AUTOSAR XML (schema 4-0-3)
package /AppMode/ApplicationSwComponentTypes
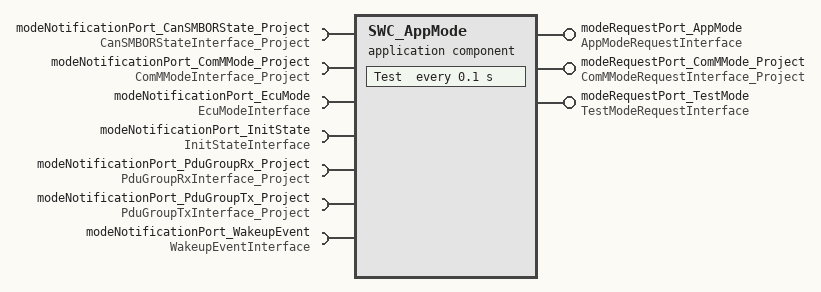
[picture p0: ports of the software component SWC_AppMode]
  application sw component type SWC_AppMode
    7 x require port:
      modeNotificationPort_CanSMBORState_Project: mode-switch-receiver-com-spec{enhanced-mode-api=true, mode-group=CanSMBORState_Project, supports-asynchronous-mode-switch=true}, required-interface=CanSMBORStateInterface_Project
      modeNotificationPort_ComMMode_Project: mode-switch-receiver-com-spec{enhanced-mode-api=true, mode-group=ComMMode_Project, supports-asynchronous-mode-switch=true}, required-interface=ComMModeInterface_Project
      modeNotificationPort_EcuMode: mode-switch-receiver-com-spec{enhanced-mode-api=true, mode-group=EcuMode, supports-asynchronous-mode-switch=true}, required-interface=EcuModeInterface
      modeNotificationPort_InitState: mode-switch-receiver-com-spec{enhanced-mode-api=true, mode-group=InitState, supports-asynchronous-mode-switch=true}, required-interface=InitStateInterface
      modeNotificationPort_PduGroupRx_Project: mode-switch-receiver-com-spec{enhanced-mode-api=true, mode-group=PduGroupRx_Project, supports-asynchronous-mode-switch=true}, required-interface=PduGroupRxInterface_Project
      modeNotificationPort_PduGroupTx_Project: mode-switch-receiver-com-spec{enhanced-mode-api=true, mode-group=PduGroupTx_Project, supports-asynchronous-mode-switch=true}, required-interface=PduGroupTxInterface_Project
      modeNotificationPort_WakeupEvent: mode-switch-receiver-com-spec{enhanced-mode-api=true, mode-group=WakeupEvent, supports-asynchronous-mode-switch=true}, required-interface=WakeupEventInterface
    provide port modeRequestPort_AppMode: nonqueued-sender-com-spec=AppMode, provided-interface=AppModeRequestInterface
    provide port modeRequestPort_ComMMode_Project: nonqueued-sender-com-spec=ComMMode_Project, provided-interface=ComMModeRequestInterface_Project
    provide port modeRequestPort_TestMode: nonqueued-sender-com-spec=TestMode, provided-interface=TestModeRequestInterface
    behavior SwcIB_AppMode: data-type-mapping=[MAP_AppMode, MAP_ComMMode, MAP_PduRouter, MAP_CanSMBORState, MAP_InitState, MAP_CanSMState, MAP_TestModeSR]
      timing event TE_AppMode_Test: start-on-event=Test, period=0.1
        disabled-mode:
          modeNotificationPort_EcuMode.EcuMode.ECUM_STATE_STARTUP_ONE
          modeNotificationPort_EcuMode.EcuMode.ECUM_STATE_STARTUP_THREE
          modeNotificationPort_EcuMode.EcuMode.ECUM_STATE_STARTUP_TWO
      7 x swc mode switch event, all with activation=ON-ENTRY:
        SMSE_Entry_EcuModeSwitched_modeNotificationPort_EcuMode_EcuMode_ECUM_STATE_PREP_SHUTDOWN: start-on-event=EcuModeSwitched, mode=modeNotificationPort_EcuMode.EcuMode.ECUM_STATE_PREP_SHUTDOWN
        SMSE_Entry_EcuModeSwitched_modeNotificationPort_EcuMode_EcuMode_ECUM_STATE_RUN: start-on-event=EcuModeSwitched, mode=modeNotificationPort_EcuMode.EcuMode.ECUM_STATE_RUN
        SMSE_Entry_EcuModeSwitched_modeNotificationPort_EcuMode_EcuMode_ECUM_STATE_SHUTDOWN: start-on-event=EcuModeSwitched, mode=modeNotificationPort_EcuMode.EcuMode.ECUM_STATE_SHUTDOWN
        SMSE_Entry_EcuModeSwitched_modeNotificationPort_EcuMode_EcuMode_ECUM_STATE_SLEEP: start-on-event=EcuModeSwitched, mode=modeNotificationPort_EcuMode.EcuMode.ECUM_STATE_SLEEP
        SMSE_Entry_InitCompleted_modeNotificationPort_InitState_InitState_COMPLETE: start-on-event=InitCompleted, mode=modeNotificationPort_InitState.InitState.COMPLETE
        SMSE_Entry_PduGroupSwitched_modeNotificationPort_PduGroupTx_Project_PduGroupTx_Project_START: start-on-event=PduGroupSwitched_Project_Tx, mode=modeNotificationPort_PduGroupTx_Project.PduGroupTx_Project.START
        SMSE_Entry_PduGroupSwitched_modeNotificationPort_PduGroupTx_Project_PduGroupTx_Project_STOP: start-on-event=PduGroupSwitched_Project_Tx, mode=modeNotificationPort_PduGroupTx_Project.PduGroupTx_Project.STOP
      8 x runnable:
        EcuModeSwitched: can-be-invoked-concurrently=true, symbol=AppMode_EcuModeSwitched
          data-send-points:
            access DSP_EcuModeSwitched_modeRequestPort_AppMode_AppMode: accessed-variable=modeRequestPort_AppMode.AppMode, scope=COMMUNICATION-INTER-ECU
            access DSP_EcuModeSwitched_modeRequestPort_ComMMode_Project_ComMMode_Project: accessed-variable=modeRequestPort_ComMMode_Project.ComMMode_Project, scope=COMMUNICATION-INTER-ECU
          mode-access-point mode-group=modeNotificationPort_EcuMode.EcuMode:
            ident MRAP_EcuModeSwitched_modeNotificationPort_EcuMode_EcuMode
        InitCompleted: can-be-invoked-concurrently=true, symbol=AppMode_InitCompleted
          data-send-points:
            access DSP_InitCompleted_modeRequestPort_AppMode_AppMode: accessed-variable=modeRequestPort_AppMode.AppMode, scope=COMMUNICATION-INTER-ECU
          mode-access-point mode-group=modeNotificationPort_InitState.InitState:
            ident MRAP_InitCompleted_modeNotificationPort_InitState_InitState
        PduGroupSwitched_Project_Tx: can-be-invoked-concurrently=true, symbol=AppMode_PduGroupSwitched_Project_Tx
          mode-access-point mode-group=modeNotificationPort_PduGroupTx_Project.PduGroupTx_Project:
            ident MRAP_PduGroupSwitched_modeNotificationPort_PduGroupTx_Project_PduGroupTx_Project
        PduGroupSwitched_Project_Rx: can-be-invoked-concurrently=true, symbol=AppMode_PduGroupSwitched_Project_Rx
          mode-access-point mode-group=modeNotificationPort_PduGroupRx_Project.PduGroupRx_Project:
            ident MRAP_PduGroupSwitched_Rx_modeNotificationPort_PduGroupRx_Project_PduGroupRx_Project
        Test: symbol=AppMode_Test
          data-send-points:
            access DSP_Test_modeRequestPort_AppMode_AppMode: accessed-variable=modeRequestPort_AppMode.AppMode, scope=COMMUNICATION-INTER-ECU
            access DSP_Test_modeRequestPort_ComMMode_Project_ComMMode_Project: accessed-variable=modeRequestPort_ComMMode_Project.ComMMode_Project, scope=COMMUNICATION-INTER-ECU
            access DSP_Test_modeRequestPort_TestMode_TestMode: accessed-variable=modeRequestPort_TestMode.TestMode, scope=COMMUNICATION-INTER-ECU
        ComMModeSwitched_Project: can-be-invoked-concurrently=true, symbol=AppMode_ComMModeSwitched_Project
          data-send-points:
            access DSP_ComMModeSwitched_Project_modeRequestPort_AppMode_AppMode: accessed-variable=modeRequestPort_AppMode.AppMode, scope=COMMUNICATION-INTER-ECU
            access DSP_ComMModeSwitched_Project_modeRequestPort_ComMMode_Project_ComMMode_Project: accessed-variable=modeRequestPort_ComMMode_Project.ComMMode_Project, scope=COMMUNICATION-INTER-ECU
          mode-access-point mode-group=modeNotificationPort_ComMMode_Project.ComMMode_Project:
            ident MRAP_ComMModeSwitched_Project_modeNotificationPort_ComMMode_Project_ComMMode_Project
        WakeupEventValidated: can-be-invoked-concurrently=true, symbol=AppMode_WakeupEventValidated
          mode-access-point mode-group=modeNotificationPort_WakeupEvent.WakeupEvent:
            ident MRAP_WakeupEventValidated_modeNotificationPort_WakeupEvent_WakeupEvent
        CanSMBorStateSwitched_Project: can-be-invoked-concurrently=true, symbol=AppMode_CanSMBorStateSwitched_Project
      swc service dependency SwcServiceDependency_BswM
        assigned-ports:
          port-prototype=modeNotificationPort_ComMMode_Project, role=Custom
          port-prototype=modeNotificationPort_EcuMode, role=Custom
          port-prototype=modeNotificationPort_InitState, role=Custom
          port-prototype=modeNotificationPort_PduGroupRx_Project, role=Custom
          port-prototype=modeNotificationPort_PduGroupTx_Project, role=Custom
          port-prototype=modeRequestPort_AppMode, role=Custom
          port-prototype=modeRequestPort_ComMMode_Project, role=Custom
          port-prototype=modeNotificationPort_WakeupEvent, role=Custom
        service-needs:
          bsw mgr needs BswMgrNeeds
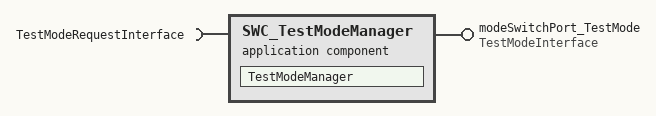
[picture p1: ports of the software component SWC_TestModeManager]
  application sw component type SWC_TestModeManager
    require port TestModeRequestInterface: nonqueued-receiver-com-spec=TestMode, required-interface=TestModeRequestInterface
    provide port modeSwitchPort_TestMode: mode-switch-sender-com-spec{enhanced-mode-api=false, mode-group=TestMode, queue-length=1}, provided-interface=TestModeInterface
    behavior InternalBehavior: data-type-mapping=[MAP_TestModeMS, MAP_TestModeSR]
      data received event DRE_TestModeManager_TestModeRequestInterface_TestMode: start-on-event=TestModeManager, data=TestModeRequestInterface.TestMode
      runnable TestModeManager: can-be-invoked-concurrently=true
        data-receive-point-by-arguments:
          access DRPBA_TestModeManager_TestModeRequestInterface_TestMode: accessed-variable=TestModeRequestInterface.TestMode, scope=COMMUNICATION-INTER-ECU
        mode switch point MSP_TestModeManager_modeSwitchPort_TestMode_TestMode: mode-group=modeSwitchPort_TestMode.TestMode
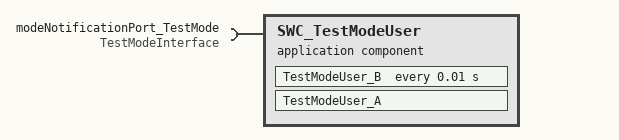
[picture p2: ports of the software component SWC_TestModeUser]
  application sw component type SWC_TestModeUser
    require port modeNotificationPort_TestMode: mode-switch-receiver-com-spec{enhanced-mode-api=true, mode-group=TestMode, supports-asynchronous-mode-switch=true}, required-interface=TestModeInterface
    behavior InternalBehavior
      timing event TE_TestModeUser_B: start-on-event=TestModeUser_B, period=0.01
      runnable TestModeUser_A
      runnable TestModeUser_B
package /AppMode/TestModeInterfaces
  app type ENUM_TestMode: category=VALUE, compu {0=MODE_READY, 1=MODE_A, 2=MODE_B}
  data type mapping set MAP_TestModeSR: data-type-map{application-data-type=ENUM_TestMode, implementation-data-type=uint8}
  mode declaration group MDG_TestMode: category=EXPLICIT_ORDER, initial-mode=MODE_READY, on-transition-value=255
    mode MODE_READY: value=0
    mode MODE_A: value=1
    mode MODE_B: value=2
  mode switch interface TestModeInterface
    mode group TestMode: type=MDG_TestMode
  sender receiver interface TestModeRequestInterface
    data TestMode: type=ENUM_TestMode
  data type mapping set MAP_TestModeMS: mode-request-type-map{implementation-data-type=uint8, mode-group=MDG_TestMode}
